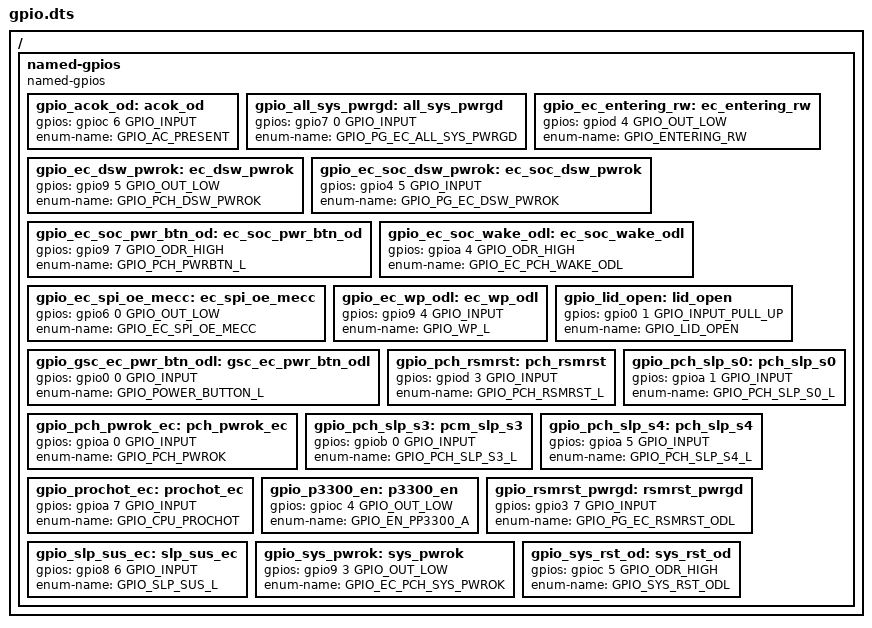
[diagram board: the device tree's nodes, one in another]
/* Copyright 2022 The Chromium OS Authors. All rights reserved.
 * Use of this source code is governed by a BSD-style license that can be
 * found in the LICENSE file.
 */

/ {
	named-gpios {
		compatible = "named-gpios";

		gpio_acok_od: acok_od {
			#gpio-cells = <0>;
			gpios = <&gpioc 6 GPIO_INPUT>;
			enum-name = "GPIO_AC_PRESENT";
		};
		gpio_all_sys_pwrgd: all_sys_pwrgd {
			#gpio-cells = <0>;
			gpios = <&gpio7 0 GPIO_INPUT>;
			enum-name = "GPIO_PG_EC_ALL_SYS_PWRGD";
		};
		gpio_ec_entering_rw: ec_entering_rw {
			#gpio-cells = <0>;
			gpios = <&gpiod 4 GPIO_OUT_LOW>;
			enum-name = "GPIO_ENTERING_RW";
		};
		gpio_ec_dsw_pwrok: ec_dsw_pwrok {
			#gpio-cells = <0>;
			gpios = <&gpio9 5 GPIO_OUT_LOW>;
			enum-name = "GPIO_PCH_DSW_PWROK";
		};
		gpio_ec_soc_dsw_pwrok: ec_soc_dsw_pwrok {
			#gpio-cells = <0>;
			gpios = <&gpio4 5 GPIO_INPUT>;
			enum-name = "GPIO_PG_EC_DSW_PWROK";
		};
		gpio_ec_soc_pwr_btn_od: ec_soc_pwr_btn_od {
			#gpio-cells = <0>;
			gpios = <&gpio9 7 GPIO_ODR_HIGH>;
			enum-name = "GPIO_PCH_PWRBTN_L";
		};
		gpio_ec_soc_wake_odl: ec_soc_wake_odl {
			#gpio-cells = <0>;
			gpios = <&gpioa 4 GPIO_ODR_HIGH>;
			enum-name = "GPIO_EC_PCH_WAKE_ODL";
		};
		gpio_ec_spi_oe_mecc: ec_spi_oe_mecc {
			#gpio-cells = <0>;
			gpios = <&gpio6 0 GPIO_OUT_LOW>;
			enum-name = "GPIO_EC_SPI_OE_MECC";
		};
		gpio_ec_wp_odl: ec_wp_odl {
			#gpio-cells = <0>;
			gpios = <&gpio9 4 GPIO_INPUT>;
			enum-name = "GPIO_WP_L";
		};
		gpio_gsc_ec_pwr_btn_odl: gsc_ec_pwr_btn_odl {
			#gpio-cells = <0>;
			gpios = <&gpio0 0 GPIO_INPUT>;
			enum-name = "GPIO_POWER_BUTTON_L";
		};
		gpio_lid_open: lid_open {
			#gpio-cells = <0>;
			gpios = <&gpio0 1 GPIO_INPUT_PULL_UP>;
			enum-name = "GPIO_LID_OPEN";
		};
		gpio_pch_rsmrst: pch_rsmrst {
			#gpio-cells = <0>;
			gpios = <&gpiod 3 GPIO_INPUT>;
			enum-name = "GPIO_PCH_RSMRST_L";
		};
		gpio_pch_pwrok_ec: pch_pwrok_ec {
			#gpio-cells = <0>;
			gpios = <&gpioa 0 GPIO_INPUT>;
			enum-name = "GPIO_PCH_PWROK";
		};
		gpio_pch_slp_s0: pch_slp_s0 {
			#gpio-cells = <0>;
			gpios = <&gpioa 1 GPIO_INPUT>;
			enum-name = "GPIO_PCH_SLP_S0_L";
		};
		gpio_pch_slp_s3: pcm_slp_s3 {
			#gpio-cells = <0>;
			gpios = <&gpiob 0 GPIO_INPUT>;
			enum-name = "GPIO_PCH_SLP_S3_L";
		};
		gpio_pch_slp_s4: pch_slp_s4 {
			#gpio-cells = <0>;
			gpios = <&gpioa 5 GPIO_INPUT>;
			enum-name = "GPIO_PCH_SLP_S4_L";
		};
		gpio_prochot_ec: prochot_ec {
			#gpio-cells = <0>;
			gpios = <&gpioa 7 GPIO_INPUT>;
			enum-name = "GPIO_CPU_PROCHOT";
		};
		gpio_p3300_en: p3300_en {
			#gpio-cells = <0>;
			gpios = <&gpioc 4 GPIO_OUT_LOW>;
			enum-name = "GPIO_EN_PP3300_A";
		};
		gpio_rsmrst_pwrgd: rsmrst_pwrgd {
			#gpio-cells = <0>;
			gpios = <&gpio3 7 GPIO_INPUT>;
			enum-name = "GPIO_PG_EC_RSMRST_ODL";
		};
		gpio_slp_sus_ec: slp_sus_ec {
			#gpio-cells = <0>;
			gpios = <&gpio8 6 GPIO_INPUT>;
			enum-name = "GPIO_SLP_SUS_L";
		};
		gpio_sys_pwrok: sys_pwrok {
			#gpio-cells = <0>;
			gpios = <&gpio9 3 GPIO_OUT_LOW>;
			enum-name = "GPIO_EC_PCH_SYS_PWROK";
		};
		gpio_sys_rst_od: sys_rst_od {
			#gpio-cells = <0>;
			gpios = <&gpioc 5 GPIO_ODR_HIGH>;
			enum-name = "GPIO_SYS_RST_ODL";
		};
	};
};
